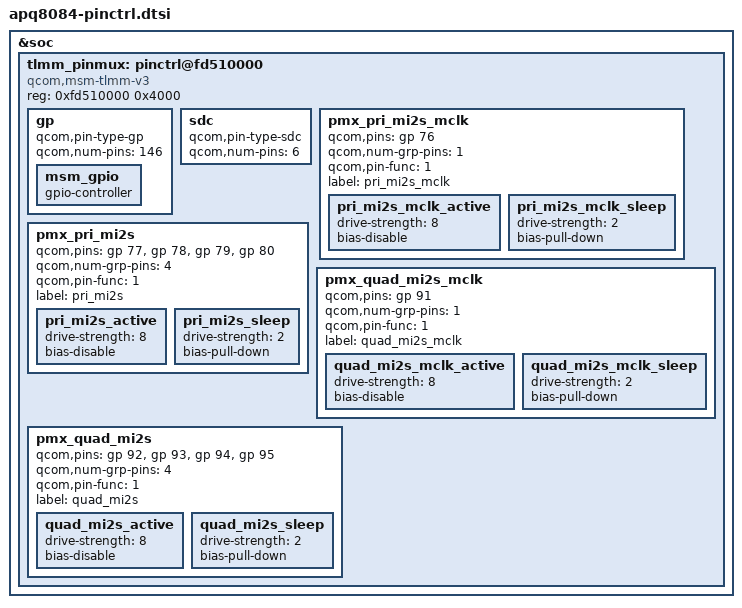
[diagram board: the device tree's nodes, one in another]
/* Copyright (c) 2014, The Linux Foundation. All rights reserved.
 *
 * This program is free software; you can redistribute it and/or modify
 * it under the terms of the GNU General Public License version 2 and
 * only version 2 as published by the Free Software Foundation.
 *
 * This program is distributed in the hope that it will be useful,
 * but WITHOUT ANY WARRANTY; without even the implied warranty of
 * MERCHANTABILITY or FITNESS FOR A PARTICULAR PURPOSE.  See the
 * GNU General Public License for more details.
 */

&soc {
	tlmm_pinmux: pinctrl@fd510000 {
		compatible = "qcom,msm-tlmm-v3";
		reg = <0xfd510000 0x4000>;

		/*General purpose pins*/
		gp: gp {
			qcom,pin-type-gp;
			qcom,num-pins = <146>;
			#qcom,pin-cells = <1>;
			msm_gpio: msm_gpio {
				gpio-controller;
				#gpio-cells = <2>;
			};
		};
		/* SDC pin type */
		sdc: sdc {
			qcom,pin-type-sdc;
			/* 0-2 for sdc1 3-5 for sdc2 */
			qcom,num-pins = <6>;
			/* Order of pins */
			/* CLK -> 0 */
			/* CMD -> 1 */
			/* DATA -> 2 */
			#qcom,pin-cells = <1>;
		};

		pmx_pri_mi2s_mclk {
			qcom,pins = <&gp 76>;
			qcom,num-grp-pins = <1>;
			qcom,pin-func = <1>;
			label = "pri_mi2s_mclk";
			pri_mi2s_mclk_active: pri_mi2s_mclk_active {
				drive-strength = <8>;	/* 8 MA */
				bias-disable;		/* No PULL */
		        };
			pri_mi2s_mclk_sleep: pri_mi2s_mclk_sleep {
				drive-strength = <2>;	/* 2 MA */
				bias-pull-down;		/* PULL DOWN */
		        };
		};

		pmx_pri_mi2s {
			qcom,pins = <&gp 77>, <&gp 78>, <&gp 79>, <&gp 80>;
			qcom,num-grp-pins = <4>;
			qcom,pin-func = <1>;
			label = "pri_mi2s";
			pri_mi2s_active: pri_mi2s_active {
				drive-strength = <8>;	/* 8 MA */
				bias-disable;		/* No PULL */
		        };
			pri_mi2s_sleep: pri_mi2s_sleep {
				drive-strength = <2>;	/* 2 MA */
				bias-pull-down;		/* PULL DOWN */
		        };
		};

		pmx_quad_mi2s_mclk {
			qcom,pins = <&gp 91>;
			qcom,num-grp-pins = <1>;
			qcom,pin-func = <1>;
			label = "quad_mi2s_mclk";
			quad_mi2s_mclk_active: quad_mi2s_mclk_active {
				drive-strength = <8>;	/* 8 MA */
				bias-disable;		/* No PULL */
		        };
			quad_mi2s_mclk_sleep: quad_mi2s_mclk_sleep {
				drive-strength = <2>;	/* 2 MA */
				bias-pull-down;		/* PULL DOWN */
		        };
		};

		pmx_quad_mi2s {
			qcom,pins = <&gp 92>, <&gp 93>, <&gp 94>, <&gp 95>;
			qcom,num-grp-pins = <4>;
			qcom,pin-func = <1>;
			label = "quad_mi2s";
			quad_mi2s_active: quad_mi2s_active {
				drive-strength = <8>;	/* 8 MA */
				bias-disable;		/* No PULL */
		        };
			quad_mi2s_sleep: quad_mi2s_sleep {
				drive-strength = <2>;	/* 2 MA */
				bias-pull-down;		/* PULL DOWN */
		        };
		};
	};
};
